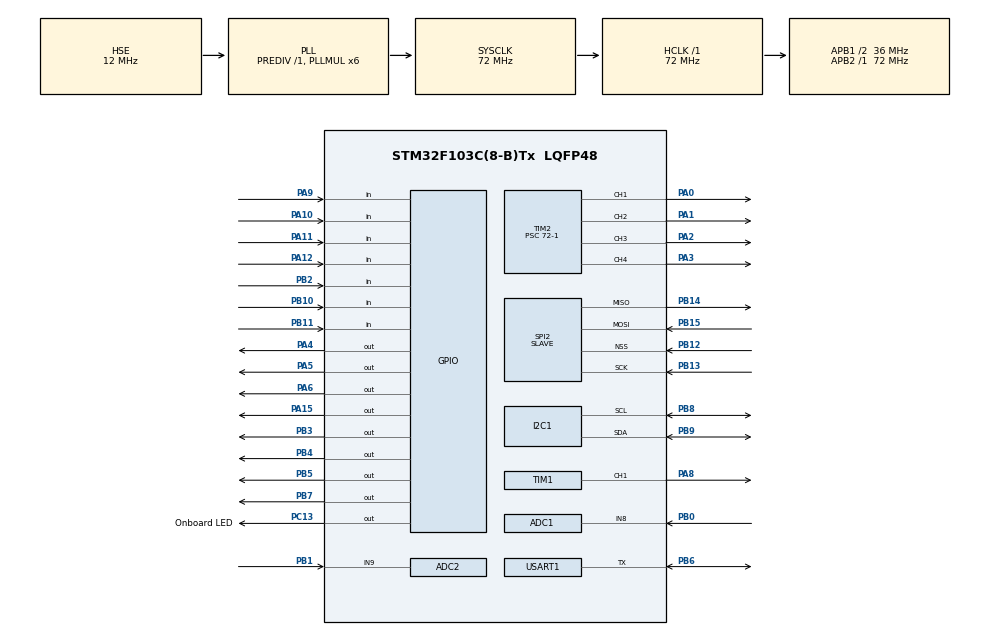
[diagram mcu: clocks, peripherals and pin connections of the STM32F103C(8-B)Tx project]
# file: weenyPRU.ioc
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ADC1.Channel-0\#ChannelRegularConversion=ADC_CHANNEL_8
ADC1.ContinuousConvMode=DISABLE
ADC1.NbrOfConversionFlag=1
ADC1.Rank-0\#ChannelRegularConversion=1
ADC1.SamplingTime-0\#ChannelRegularConversion=ADC_SAMPLETIME_239CYCLES_5
ADC1.master=1
ADC2.Channel-1\#ChannelRegularConversion=ADC_CHANNEL_9
ADC2.NbrOfConversionFlag=1
ADC2.Rank-1\#ChannelRegularConversion=1
ADC2.SamplingTime-1\#ChannelRegularConversion=ADC_SAMPLETIME_239CYCLES_5
Dma.Request0=SPI2_TX
Dma.Request1=SPI2_RX
Dma.SPI2_RX.1.Direction=DMA_PERIPH_TO_MEMORY
Dma.SPI2_RX.1.Instance=DMA1_Channel4
Dma.SPI2_RX.1.MemDataAlignment=DMA_MDATAALIGN_BYTE
Dma.SPI2_RX.1.MemInc=DMA_MINC_ENABLE
Dma.SPI2_RX.1.Mode=DMA_NORMAL
Dma.SPI2_RX.1.PeriphDataAlignment=DMA_PDATAALIGN_BYTE
Dma.SPI2_RX.1.PeriphInc=DMA_PINC_DISABLE
Dma.SPI2_RX.1.Priority=DMA_PRIORITY_VERY_HIGH
Dma.SPI2_TX.0.Direction=DMA_MEMORY_TO_PERIPH
Dma.SPI2_TX.0.Instance=DMA1_Channel5
Dma.SPI2_TX.0.MemDataAlignment=DMA_MDATAALIGN_BYTE
Dma.SPI2_TX.0.MemInc=DMA_MINC_ENABLE
Dma.SPI2_TX.0.Mode=DMA_NORMAL
Dma.SPI2_TX.0.PeriphDataAlignment=DMA_PDATAALIGN_BYTE
Dma.SPI2_TX.0.PeriphInc=DMA_PINC_DISABLE
Dma.SPI2_TX.0.Priority=DMA_PRIORITY_VERY_HIGH
Mcu.Family=STM32F1
Mcu.Name=STM32F103C(8-B)Tx
Mcu.Package=LQFP48
NVIC.DMA1_Channel4_IRQn=true\:0\:0\:false\:false\:true\:false\:true\:true
NVIC.DMA1_Channel5_IRQn=true\:0\:0\:false\:false\:true\:false\:true\:true
NVIC.PriorityGroup=NVIC_PRIORITYGROUP_4
NVIC.TIM3_IRQn=true\:0\:0\:false\:false\:true\:true\:true\:true
NVIC.TIM4_IRQn=true\:0\:0\:false\:false\:true\:true\:true\:true
PA0-WKUP.Signal=S_TIM2_CH1_ETR
PA1.Signal=S_TIM2_CH2
PA10.GPIO_PuPd=GPIO_PULLUP
PA10.Signal=GPIO_Input
PA11.GPIO_PuPd=GPIO_PULLUP
PA11.Signal=GPIO_Input
PA12.GPIO_PuPd=GPIO_PULLUP
PA12.Signal=GPIO_Input
PA13.Mode=Serial_Wire
PA13.Signal=SYS_JTMS-SWDIO
PA14.Mode=Serial_Wire
PA14.Signal=SYS_JTCK-SWCLK
PA15.Signal=GPIO_Output
PA2.Signal=S_TIM2_CH3
PA3.Signal=S_TIM2_CH4
PA4.Signal=GPIO_Output
PA5.Signal=GPIO_Output
PA6.Signal=GPIO_Output
PA8.Signal=S_TIM1_CH1
PA9.GPIO_PuPd=GPIO_PULLUP
PA9.Signal=GPIO_Input
PB0.Signal=ADCx_IN8
PB1.Signal=ADCx_IN9
PB10.GPIO_PuPd=GPIO_PULLUP
PB10.Signal=GPIO_Input
PB11.GPIO_PuPd=GPIO_PULLUP
PB11.Signal=GPIO_Input
PB12.Mode=NSS_Signal_Hard_Input
PB12.Signal=SPI2_NSS
PB13.Mode=Full_Duplex_Slave
PB13.Signal=SPI2_SCK
PB14.Mode=Full_Duplex_Slave
PB14.Signal=SPI2_MISO
PB15.Mode=Full_Duplex_Slave
PB15.Signal=SPI2_MOSI
PB2.GPIO_PuPd=GPIO_PULLUP
PB2.Signal=GPIO_Input
PB3.Signal=GPIO_Output
PB4.Signal=GPIO_Output
PB5.Signal=GPIO_Output
PB6.Mode=Half_duplex(single_wire_mode)
PB6.Signal=USART1_TX
PB7.Signal=GPIO_Output
PB8.Mode=I2C
PB8.Signal=I2C1_SCL
PB9.Mode=I2C
PB9.Signal=I2C1_SDA
PC13-TAMPER-RTC.GPIO_Label=Onboard LED
PC13-TAMPER-RTC.Signal=GPIO_Output
PD0-OSC_IN.Mode=HSE-External-Oscillator
PD0-OSC_IN.Signal=RCC_OSC_IN
PD1-OSC_OUT.Mode=HSE-External-Oscillator
PD1-OSC_OUT.Signal=RCC_OSC_OUT
ProjectManager.HeapSize=0x200
ProjectManager.StackSize=0x400
ProjectManager.TargetToolchain=STM32CubeIDE
RCC.ADCPresc=RCC_ADCPCLK2_DIV6
RCC.AHBFreq_Value=72000000
RCC.APB1CLKDivider=RCC_HCLK_DIV2
RCC.APB1Freq_Value=36000000
RCC.APB1TimFreq_Value=72000000
RCC.APB2Freq_Value=72000000
RCC.APB2TimFreq_Value=72000000
RCC.HCLKFreq_Value=72000000
RCC.HSE_VALUE=12000000
RCC.PLLMUL=RCC_PLL_MUL6
RCC.PLLSourceVirtual=RCC_PLLSOURCE_HSE
RCC.SYSCLKFreq_VALUE=72000000
RCC.SYSCLKSource=RCC_SYSCLKSOURCE_PLLCLK
RCC.USBFreq_Value=72000000
SH.ADCx_IN8.0=ADC1_IN8,IN8
SH.ADCx_IN9.0=ADC2_IN9,IN9
SH.S_TIM1_CH1.0=TIM1_CH1,PWM Generation1 CH1
SH.S_TIM2_CH1_ETR.0=TIM2_CH1,PWM Generation1 CH1
SH.S_TIM2_CH2.0=TIM2_CH2,PWM Generation2 CH2
SH.S_TIM2_CH3.0=TIM2_CH3,PWM Generation3 CH3
SH.S_TIM2_CH4.0=TIM2_CH4,PWM Generation4 CH4
SPI2.Direction=SPI_DIRECTION_2LINES
SPI2.Mode=SPI_MODE_SLAVE
SPI2.VirtualNSS=VM_NSSHARD
SPI2.VirtualType=VM_SLAVE
TIM1.AutoReloadPreload=TIM_AUTORELOAD_PRELOAD_DISABLE
TIM1.Channel-PWM\ Generation1\ CH1=TIM_CHANNEL_1
TIM1.Period=3600
TIM1.Prescaler=1
TIM1.Pulse-PWM\ Generation1\ CH1=0
TIM2.AutoReloadPreload=TIM_AUTORELOAD_PRELOAD_ENABLE
TIM2.Channel-PWM\ Generation1\ CH1=TIM_CHANNEL_1
TIM2.Channel-PWM\ Generation2\ CH2=TIM_CHANNEL_2
TIM2.Channel-PWM\ Generation3\ CH3=TIM_CHANNEL_3
TIM2.Channel-PWM\ Generation4\ CH4=TIM_CHANNEL_4
TIM2.OC1Preload_PWM=DISABLE
TIM2.OC2Preload_PWM=DISABLE
TIM2.OC3Preload_PWM=DISABLE
TIM2.OC4Preload_PWM=DISABLE
TIM2.Prescaler=72-1
TIM2.Pulse-PWM\ Generation1\ CH1=0
TIM2.Pulse-PWM\ Generation2\ CH2=0
TIM2.Pulse-PWM\ Generation3\ CH3=0
TIM2.Pulse-PWM\ Generation4\ CH4=0
TIM3.Channel-Output\ Compare1\ No\ Output=TIM_CHANNEL_1
TIM3.Period=1000-1
TIM3.Prescaler=72-1
TIM4.Channel-Output\ Compare1\ No\ Output=TIM_CHANNEL_1
TIM4.Period=20-1
TIM4.Prescaler=72-1
USART1.BaudRate=230400
USART1.VirtualMode=VM_ASYNC
VP_TIM3_VS_no_output1.Mode=Output Compare1 No Output
VP_TIM4_VS_no_output1.Mode=Output Compare1 No Output
board=custom

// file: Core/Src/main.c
/* USER CODE BEGIN Header */
/**
  ******************************************************************************
  * @file           : main.c
  * @brief          : Main program body
  ******************************************************************************
  * @attention
  *
  * Copyright (c) 2023 STMicroelectronics.
  * All rights reserved.
  *
  * This software is licensed under terms that can be found in the LICENSE file
  * in the root directory of this software component.
  * If no LICENSE file comes with this software, it is provided AS-IS.
  *
  ******************************************************************************
  */
#include <stdio.h>
/* USER CODE END Header */
#include "main.h"

/* USER CODE BEGIN Includes */
#include "config.h"
#include "led.h"
#include "core.h"
#include "TMC2209.h"
/* USER CODE END Includes */

ADC_HandleTypeDef hadc1;
ADC_HandleTypeDef hadc2;

I2C_HandleTypeDef hi2c1;

SPI_HandleTypeDef hspi2;
DMA_HandleTypeDef hdma_spi2_tx;
DMA_HandleTypeDef hdma_spi2_rx;

TIM_HandleTypeDef htim1;
TIM_HandleTypeDef htim2;
TIM_HandleTypeDef htim3;
TIM_HandleTypeDef htim4;

UART_HandleTypeDef huart1;

void SystemClock_Config(void);
static void MX_GPIO_Init(void);
static void MX_DMA_Init(void);
static void MX_SPI2_Init(void);
static void MX_TIM3_Init(void);
static void MX_TIM4_Init(void);
static void MX_TIM2_Init(void);
#ifdef USE_ANALOG
static void MX_ADC1_Init(void);
static void MX_ADC2_Init(void);
#endif
#ifdef USE_PWM
static void MX_TIM1_Init(void);
#endif
#ifdef USE_UART_TMC
static void MX_USART1_UART_Init(void);
#endif
#if (defined(USE_I2C_XGZP) || defined(USE_I2C_DS3502))
static void MX_I2C1_Init(void);
#endif

int main(void)
{

  /* MCU Configuration--------------------------------------------------------*/

  /* Reset of all peripherals, Initializes the Flash interface and the Systick. */
  HAL_Init();

  /* Configure the system clock */
  SystemClock_Config();

  /* Initialize all configured peripherals */
  MX_GPIO_Init();
  MX_DMA_Init();
  MX_SPI2_Init();
  MX_TIM3_Init();
  MX_TIM4_Init();
  MX_TIM2_Init();
#ifdef USE_ANALOG
  MX_ADC1_Init();
  MX_ADC2_Init();
#endif
#ifdef USE_PWM
  MX_TIM1_Init();
#endif
#ifdef USE_UART_TMC
  MX_USART1_UART_Init();
#endif
#if (defined(USE_I2C_XGZP) || defined(USE_I2C_DS3502))
  MX_I2C1_Init();
#endif
  /* USER CODE BEGIN 2 */

  doSetup();

  /* USER CODE END 2 */

  /* Infinite loop */
  /* USER CODE BEGIN WHILE */
  while (1)
  {
	  doMainLoopTasks();

    /* USER CODE END WHILE */

  }
}

void SystemClock_Config(void)
{
  RCC_OscInitTypeDef RCC_OscInitStruct = {0};
  RCC_ClkInitTypeDef RCC_ClkInitStruct = {0};
  RCC_PeriphCLKInitTypeDef PeriphClkInit = {0};

  /** Initializes the RCC Oscillators according to the specified parameters
  * in the RCC_OscInitTypeDef structure.
  */
  RCC_OscInitStruct.OscillatorType = RCC_OSCILLATORTYPE_HSE;
  RCC_OscInitStruct.HSEState = RCC_HSE_ON;
  RCC_OscInitStruct.HSEPredivValue = RCC_HSE_PREDIV_DIV1;
  RCC_OscInitStruct.HSIState = RCC_HSI_ON;
  RCC_OscInitStruct.PLL.PLLState = RCC_PLL_ON;
  RCC_OscInitStruct.PLL.PLLSource = RCC_PLLSOURCE_HSE;
  RCC_OscInitStruct.PLL.PLLMUL = RCC_PLL_MUL6;
  if (HAL_RCC_OscConfig(&RCC_OscInitStruct) != HAL_OK)
  {
    Error_Handler();
  }

  /** Initializes the CPU, AHB and APB buses clocks
  */
  RCC_ClkInitStruct.ClockType = RCC_CLOCKTYPE_HCLK|RCC_CLOCKTYPE_SYSCLK
                              |RCC_CLOCKTYPE_PCLK1|RCC_CLOCKTYPE_PCLK2;
  RCC_ClkInitStruct.SYSCLKSource = RCC_SYSCLKSOURCE_PLLCLK;
  RCC_ClkInitStruct.AHBCLKDivider = RCC_SYSCLK_DIV1;
  RCC_ClkInitStruct.APB1CLKDivider = RCC_HCLK_DIV2;
  RCC_ClkInitStruct.APB2CLKDivider = RCC_HCLK_DIV1;

  if (HAL_RCC_ClockConfig(&RCC_ClkInitStruct, FLASH_LATENCY_2) != HAL_OK)
  {
    Error_Handler();
  }
  PeriphClkInit.PeriphClockSelection = RCC_PERIPHCLK_ADC;
  PeriphClkInit.AdcClockSelection = RCC_ADCPCLK2_DIV6;
  if (HAL_RCCEx_PeriphCLKConfig(&PeriphClkInit) != HAL_OK)
  {
    Error_Handler();
  }
}

#ifdef USE_ANALOG
static void MX_ADC1_Init(void)
{

  ADC_ChannelConfTypeDef sConfig = {0};

  /** Common config
  */
  hadc1.Instance = ADC1;
  hadc1.Init.ScanConvMode = ADC_SCAN_DISABLE;
  hadc1.Init.ContinuousConvMode = DISABLE;
  hadc1.Init.DiscontinuousConvMode = DISABLE;
  hadc1.Init.ExternalTrigConv = ADC_SOFTWARE_START;
  hadc1.Init.DataAlign = ADC_DATAALIGN_RIGHT;
  hadc1.Init.NbrOfConversion = 1;
  if (HAL_ADC_Init(&hadc1) != HAL_OK)
  {
    Error_Handler();
  }

  /** Configure Regular Channel
  */
  sConfig.Channel = ADC_CHANNEL_8;
  sConfig.Rank = ADC_REGULAR_RANK_1;
  sConfig.SamplingTime = ADC_SAMPLETIME_239CYCLES_5;
  if (HAL_ADC_ConfigChannel(&hadc1, &sConfig) != HAL_OK)
  {
    Error_Handler();
  }

}
#endif

#ifdef USE_ANALOG
static void MX_ADC2_Init(void)
{

  ADC_ChannelConfTypeDef sConfig = {0};

  /** Common config
  */
  hadc2.Instance = ADC2;
  hadc2.Init.ScanConvMode = ADC_SCAN_DISABLE;
  hadc2.Init.ContinuousConvMode = DISABLE;
  hadc2.Init.DiscontinuousConvMode = DISABLE;
  hadc2.Init.ExternalTrigConv = ADC_SOFTWARE_START;
  hadc2.Init.DataAlign = ADC_DATAALIGN_RIGHT;
  hadc2.Init.NbrOfConversion = 1;
  if (HAL_ADC_Init(&hadc2) != HAL_OK)
  {
    Error_Handler();
  }

  /** Configure Regular Channel
  */
  sConfig.Channel = ADC_CHANNEL_9;
  sConfig.Rank = ADC_REGULAR_RANK_1;
  sConfig.SamplingTime = ADC_SAMPLETIME_239CYCLES_5;
  if (HAL_ADC_ConfigChannel(&hadc2, &sConfig) != HAL_OK)
  {
    Error_Handler();
  }

}
#endif

#if (defined(USE_I2C_XGZP) || defined(USE_I2C_DS3502))
static void MX_I2C1_Init(void)
{

  /* USER CODE BEGIN I2C1_Init 0 */
#if !(defined(USE_I2C_XGZP) || defined(USE_I2C_DS3502))
	return; // leave PB8,PB9 available for digital I/O
#endif
  /* USER CODE END I2C1_Init 0 */

  hi2c1.Instance = I2C1;
  hi2c1.Init.ClockSpeed = 100000;
  hi2c1.Init.DutyCycle = I2C_DUTYCYCLE_2;
  hi2c1.Init.OwnAddress1 = 0;
  hi2c1.Init.AddressingMode = I2C_ADDRESSINGMODE_7BIT;
  hi2c1.Init.DualAddressMode = I2C_DUALADDRESS_DISABLE;
  hi2c1.Init.OwnAddress2 = 0;
  hi2c1.Init.GeneralCallMode = I2C_GENERALCALL_DISABLE;
  hi2c1.Init.NoStretchMode = I2C_NOSTRETCH_DISABLE;
  if (HAL_I2C_Init(&hi2c1) != HAL_OK)
  {
    Error_Handler();
  }

}
#endif

void MX_SPI2_Init(void)
{

  /* SPI2 parameter configuration*/
  hspi2.Instance = SPI2;
  hspi2.Init.Mode = SPI_MODE_SLAVE;
  hspi2.Init.Direction = SPI_DIRECTION_2LINES;
  hspi2.Init.DataSize = SPI_DATASIZE_8BIT;
  hspi2.Init.CLKPolarity = SPI_POLARITY_LOW;
  hspi2.Init.CLKPhase = SPI_PHASE_1EDGE;
  hspi2.Init.NSS = SPI_NSS_HARD_INPUT;
  hspi2.Init.FirstBit = SPI_FIRSTBIT_MSB;
  hspi2.Init.TIMode = SPI_TIMODE_DISABLE;
  hspi2.Init.CRCCalculation = SPI_CRCCALCULATION_DISABLE;
  hspi2.Init.CRCPolynomial = 10;
  if (HAL_SPI_Init(&hspi2) != HAL_OK)
  {
    Error_Handler();
  }
  /* USER CODE BEGIN SPI2_Init 2 */

  //hspi2.Init.NSS = SPI_NSS_HARD_INPUT;

  /* USER CODE END SPI2_Init 2 */

}

#ifdef USE_PWM
static void MX_TIM1_Init(void)
{
  TIM_MasterConfigTypeDef sMasterConfig = {0};
  TIM_OC_InitTypeDef sConfigOC = {0};
  TIM_BreakDeadTimeConfigTypeDef sBreakDeadTimeConfig = {0};

  htim1.Instance = TIM1;
  htim1.Init.Prescaler = 1;
  htim1.Init.CounterMode = TIM_COUNTERMODE_UP;
  htim1.Init.Period = 3600;
  htim1.Init.ClockDivision = TIM_CLOCKDIVISION_DIV1;
  htim1.Init.RepetitionCounter = 0;
  htim1.Init.AutoReloadPreload = TIM_AUTORELOAD_PRELOAD_DISABLE;
  if (HAL_TIM_PWM_Init(&htim1) != HAL_OK)
  {
    Error_Handler();
  }
  sMasterConfig.MasterOutputTrigger = TIM_TRGO_RESET;
  sMasterConfig.MasterSlaveMode = TIM_MASTERSLAVEMODE_DISABLE;
  if (HAL_TIMEx_MasterConfigSynchronization(&htim1, &sMasterConfig) != HAL_OK)
  {
    Error_Handler();
  }
  sConfigOC.OCMode = TIM_OCMODE_PWM1;
  sConfigOC.Pulse = 0;
  sConfigOC.OCPolarity = TIM_OCPOLARITY_HIGH;
  sConfigOC.OCNPolarity = TIM_OCNPOLARITY_HIGH;
  sConfigOC.OCFastMode = TIM_OCFAST_DISABLE;
  sConfigOC.OCIdleState = TIM_OCIDLESTATE_RESET;
  sConfigOC.OCNIdleState = TIM_OCNIDLESTATE_RESET;
  if (HAL_TIM_PWM_ConfigChannel(&htim1, &sConfigOC, TIM_CHANNEL_1) != HAL_OK)
  {
    Error_Handler();
  }
  sBreakDeadTimeConfig.OffStateRunMode = TIM_OSSR_DISABLE;
  sBreakDeadTimeConfig.OffStateIDLEMode = TIM_OSSI_DISABLE;
  sBreakDeadTimeConfig.LockLevel = TIM_LOCKLEVEL_OFF;
  sBreakDeadTimeConfig.DeadTime = 0;
  sBreakDeadTimeConfig.BreakState = TIM_BREAK_DISABLE;
  sBreakDeadTimeConfig.BreakPolarity = TIM_BREAKPOLARITY_HIGH;
  sBreakDeadTimeConfig.AutomaticOutput = TIM_AUTOMATICOUTPUT_DISABLE;
  if (HAL_TIMEx_ConfigBreakDeadTime(&htim1, &sBreakDeadTimeConfig) != HAL_OK)
  {
    Error_Handler();
  }

  HAL_TIM_MspPostInit(&htim1);
}
#endif

static void MX_TIM2_Init(void)
{

  TIM_MasterConfigTypeDef sMasterConfig = {0};
  TIM_OC_InitTypeDef sConfigOC = {0};

  htim2.Instance = TIM2;
  htim2.Init.Prescaler = 72-1;
  htim2.Init.CounterMode = TIM_COUNTERMODE_UP;
  htim2.Init.Period = 65535;
  htim2.Init.ClockDivision = TIM_CLOCKDIVISION_DIV1;
  htim2.Init.AutoReloadPreload = TIM_AUTORELOAD_PRELOAD_ENABLE;
  if (HAL_TIM_PWM_Init(&htim2) != HAL_OK)
  {
    Error_Handler();
  }
  sMasterConfig.MasterOutputTrigger = TIM_TRGO_RESET;
  sMasterConfig.MasterSlaveMode = TIM_MASTERSLAVEMODE_DISABLE;
  if (HAL_TIMEx_MasterConfigSynchronization(&htim2, &sMasterConfig) != HAL_OK)
  {
    Error_Handler();
  }
  sConfigOC.OCMode = TIM_OCMODE_PWM1;
  sConfigOC.Pulse = 0;
  sConfigOC.OCPolarity = TIM_OCPOLARITY_HIGH;
  sConfigOC.OCFastMode = TIM_OCFAST_DISABLE;
  if (HAL_TIM_PWM_ConfigChannel(&htim2, &sConfigOC, TIM_CHANNEL_1) != HAL_OK)
  {
    Error_Handler();
  }
  __HAL_TIM_DISABLE_OCxPRELOAD(&htim2, TIM_CHANNEL_1);
  if (HAL_TIM_PWM_ConfigChannel(&htim2, &sConfigOC, TIM_CHANNEL_2) != HAL_OK)
  {
    Error_Handler();
  }
  __HAL_TIM_DISABLE_OCxPRELOAD(&htim2, TIM_CHANNEL_2);
  if (HAL_TIM_PWM_ConfigChannel(&htim2, &sConfigOC, TIM_CHANNEL_3) != HAL_OK)
  {
    Error_Handler();
  }
  __HAL_TIM_DISABLE_OCxPRELOAD(&htim2, TIM_CHANNEL_3);
  if (HAL_TIM_PWM_ConfigChannel(&htim2, &sConfigOC, TIM_CHANNEL_4) != HAL_OK)
  {
    Error_Handler();
  }
  __HAL_TIM_DISABLE_OCxPRELOAD(&htim2, TIM_CHANNEL_4);
  HAL_TIM_MspPostInit(&htim2);

}

static void MX_TIM3_Init(void)
{

  TIM_MasterConfigTypeDef sMasterConfig = {0};
  TIM_OC_InitTypeDef sConfigOC = {0};

  htim3.Instance = TIM3;
  htim3.Init.Prescaler = 72-1;
  htim3.Init.CounterMode = TIM_COUNTERMODE_UP;
  htim3.Init.Period = 1000-1;
  htim3.Init.ClockDivision = TIM_CLOCKDIVISION_DIV1;
  htim3.Init.AutoReloadPreload = TIM_AUTORELOAD_PRELOAD_DISABLE;
  if (HAL_TIM_OC_Init(&htim3) != HAL_OK)
  {
    Error_Handler();
  }
  sMasterConfig.MasterOutputTrigger = TIM_TRGO_RESET;
  sMasterConfig.MasterSlaveMode = TIM_MASTERSLAVEMODE_DISABLE;
  if (HAL_TIMEx_MasterConfigSynchronization(&htim3, &sMasterConfig) != HAL_OK)
  {
    Error_Handler();
  }
  sConfigOC.OCMode = TIM_OCMODE_TIMING;
  sConfigOC.Pulse = 0;
  sConfigOC.OCPolarity = TIM_OCPOLARITY_HIGH;
  sConfigOC.OCFastMode = TIM_OCFAST_DISABLE;
  if (HAL_TIM_OC_ConfigChannel(&htim3, &sConfigOC, TIM_CHANNEL_1) != HAL_OK)
  {
    Error_Handler();
  }

}

static void MX_TIM4_Init(void)
{

  TIM_MasterConfigTypeDef sMasterConfig = {0};
  TIM_OC_InitTypeDef sConfigOC = {0};

  htim4.Instance = TIM4;
  htim4.Init.Prescaler = 72-1;
  htim4.Init.CounterMode = TIM_COUNTERMODE_UP;
  htim4.Init.Period = 20-1;
  htim4.Init.ClockDivision = TIM_CLOCKDIVISION_DIV1;
  htim4.Init.AutoReloadPreload = TIM_AUTORELOAD_PRELOAD_DISABLE;
  if (HAL_TIM_OC_Init(&htim4) != HAL_OK)
  {
    Error_Handler();
  }
  sMasterConfig.MasterOutputTrigger = TIM_TRGO_RESET;
  sMasterConfig.MasterSlaveMode = TIM_MASTERSLAVEMODE_DISABLE;
  if (HAL_TIMEx_MasterConfigSynchronization(&htim4, &sMasterConfig) != HAL_OK)
  {
    Error_Handler();
  }
  sConfigOC.OCMode = TIM_OCMODE_TIMING;
  sConfigOC.Pulse = 0;
  sConfigOC.OCPolarity = TIM_OCPOLARITY_HIGH;
  sConfigOC.OCFastMode = TIM_OCFAST_DISABLE;
  if (HAL_TIM_OC_ConfigChannel(&htim4, &sConfigOC, TIM_CHANNEL_1) != HAL_OK)
  {
    Error_Handler();
  }

}

#ifdef USE_UART_TMC
static void MX_USART1_UART_Init(void)
{

  /* USER CODE BEGIN USART1_Init 0 */
#ifndef USE_UART_TMC
	return; // leave PB6 available for digital I/O
#endif
  /* USER CODE END USART1_Init 0 */

  huart1.Instance = USART1;
  huart1.Init.BaudRate = 230400;
  huart1.Init.WordLength = UART_WORDLENGTH_8B;
  huart1.Init.StopBits = UART_STOPBITS_1;
  huart1.Init.Parity = UART_PARITY_NONE;
  huart1.Init.Mode = UART_MODE_TX_RX;
  huart1.Init.HwFlowCtl = UART_HWCONTROL_NONE;
  huart1.Init.OverSampling = UART_OVERSAMPLING_16;
  if (HAL_HalfDuplex_Init(&huart1) != HAL_OK)
  {
    Error_Handler();
  }

}
#endif

static void MX_DMA_Init(void)
{
  __HAL_RCC_DMA1_CLK_ENABLE();

  // NVIC priorities are set in core.c

  HAL_NVIC_EnableIRQ(DMA1_Channel4_IRQn); // comms rx
  HAL_NVIC_EnableIRQ(DMA1_Channel5_IRQn); // comms tx

#ifdef USE_LOADCELL
  HAL_NVIC_EnableIRQ(DMA1_Channel2_IRQn); // SPI1 RX
  HAL_NVIC_EnableIRQ(DMA1_Channel3_IRQn); // SPI1 TX
#endif

}

static void MX_GPIO_Init(void)
{
  __HAL_RCC_GPIOC_CLK_ENABLE();
  __HAL_RCC_GPIOD_CLK_ENABLE();
  __HAL_RCC_GPIOA_CLK_ENABLE();
  __HAL_RCC_GPIOB_CLK_ENABLE();

  // The pins below will always be GPIO.
  // Other GPIO that depend on enabled features are set up in setupGPIOPins()

  GPIO_InitTypeDef GPIO_InitStruct = {0};

  // PC13 is the onboard LED to show active SPI connection to RPi
  GPIO_InitStruct.Pin = Onboard_LED_Pin;
  GPIO_InitStruct.Mode = GPIO_MODE_OUTPUT_PP;
  GPIO_InitStruct.Pull = GPIO_NOPULL;
  GPIO_InitStruct.Speed = GPIO_SPEED_FREQ_LOW;
  HAL_GPIO_Init(Onboard_LED_GPIO_Port, &GPIO_InitStruct);

  // PA4 PA5 PA6 are stepper direction pins
  GPIO_InitStruct.Pin = GPIO_PIN_4|GPIO_PIN_5|GPIO_PIN_6;
  GPIO_InitStruct.Mode = GPIO_MODE_OUTPUT_PP;
  GPIO_InitStruct.Pull = GPIO_NOPULL;
  GPIO_InitStruct.Speed = GPIO_SPEED_FREQ_LOW;
  HAL_GPIO_Init(GPIOA, &GPIO_InitStruct);

  // PB5 is stepper direction pin
  GPIO_InitStruct.Pin = GPIO_PIN_5;
  GPIO_InitStruct.Mode = GPIO_MODE_OUTPUT_PP;
  GPIO_InitStruct.Pull = GPIO_NOPULL;
  GPIO_InitStruct.Speed = GPIO_SPEED_FREQ_LOW;
  HAL_GPIO_Init(GPIOB, &GPIO_InitStruct);

  /*
  GPIO_InitTypeDef GPIO_InitStruct = {0};
  //Configure GPIO pin Output Level
  HAL_GPIO_WritePin(Onboard_LED_GPIO_Port, Onboard_LED_Pin, GPIO_PIN_RESET);

  //Configure GPIO pin Output Level
  HAL_GPIO_WritePin(GPIOA, GPIO_PIN_4|GPIO_PIN_5|GPIO_PIN_6|GPIO_PIN_15, GPIO_PIN_RESET);

  //Configure GPIO pin Output Level
  HAL_GPIO_WritePin(GPIOB, GPIO_PIN_3|GPIO_PIN_4|GPIO_PIN_5|GPIO_PIN_7, GPIO_PIN_RESET);

  //Configure GPIO pin : Onboard_LED_Pin
  GPIO_InitStruct.Pin = Onboard_LED_Pin;
  GPIO_InitStruct.Mode = GPIO_MODE_OUTPUT_PP;
  GPIO_InitStruct.Pull = GPIO_NOPULL;
  GPIO_InitStruct.Speed = GPIO_SPEED_FREQ_LOW;
  HAL_GPIO_Init(Onboard_LED_GPIO_Port, &GPIO_InitStruct);

  //Configure GPIO pins : PA4 PA5 PA6 PA15
  GPIO_InitStruct.Pin = GPIO_PIN_4|GPIO_PIN_5|GPIO_PIN_6|GPIO_PIN_15;
  GPIO_InitStruct.Mode = GPIO_MODE_OUTPUT_PP;
  GPIO_InitStruct.Pull = GPIO_NOPULL;
  GPIO_InitStruct.Speed = GPIO_SPEED_FREQ_LOW;
  HAL_GPIO_Init(GPIOA, &GPIO_InitStruct);

  //Configure GPIO pins : PB2 PB10 PB11
  GPIO_InitStruct.Pin = GPIO_PIN_2|GPIO_PIN_10|GPIO_PIN_11;
  GPIO_InitStruct.Mode = GPIO_MODE_INPUT;
  GPIO_InitStruct.Pull = GPIO_PULLUP;
  HAL_GPIO_Init(GPIOB, &GPIO_InitStruct);

  //Configure GPIO pins : PA9 PA10 PA11 PA12
  GPIO_InitStruct.Pin = GPIO_PIN_9|GPIO_PIN_10|GPIO_PIN_11|GPIO_PIN_12;
  GPIO_InitStruct.Mode = GPIO_MODE_INPUT;
  GPIO_InitStruct.Pull = GPIO_PULLUP;
  HAL_GPIO_Init(GPIOA, &GPIO_InitStruct);

  //Configure GPIO pins : PB3 PB4 PB5 PB7
  GPIO_InitStruct.Pin = GPIO_PIN_3|GPIO_PIN_4|GPIO_PIN_5|GPIO_PIN_7;
  GPIO_InitStruct.Mode = GPIO_MODE_OUTPUT_PP;
  GPIO_InitStruct.Pull = GPIO_NOPULL;
  GPIO_InitStruct.Speed = GPIO_SPEED_FREQ_LOW;
  HAL_GPIO_Init(GPIOB, &GPIO_InitStruct);
  */
}

void Error_Handler(void)
{
  __disable_irq();
  while (1)
  {
  }
}
